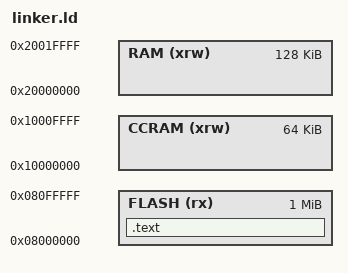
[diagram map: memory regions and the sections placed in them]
_estack = 0x20020000;

MEMORY
{
FLASH (rx) : ORIGIN = 0x08000000, LENGTH = 1024K
CCRAM (xrw) : ORIGIN = 0x10000000, LENGTH = 64K
RAM (xrw) : ORIGIN = 0x20000000, LENGTH = 128K
}

SECTIONS
{

.text : {
	*(.text)
} > FLASH

}
